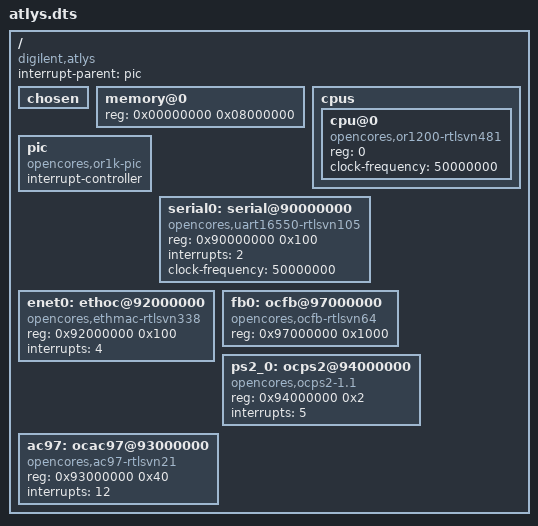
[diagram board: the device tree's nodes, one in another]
/dts-v1/;
/ {
	compatible = "digilent,atlys";

	#address-cells = <1>;
	#size-cells = <1>;
	interrupt-parent = <&pic>;

	chosen {
	};

	memory@0 {
		device_type = "memory";
		reg = <0x00000000 0x08000000>;
	};

	cpus {
		#address-cells = <1>;
		#size-cells = <0>;
		cpu@0 {
			compatible = "opencores,or1200-rtlsvn481";
			reg = <0>;
			clock-frequency = <50000000>;
		};
	};

	/*
	 * OR1K PIC is built into CPU and accessed via special purpose
	 * registers.  It is not addressable and, hence, has no 'reg'
	 * property.
	 */
	pic: pic {
		compatible = "opencores,or1k-pic";
		#interrupt-cells = <1>;
		interrupt-controller;
	};

	serial0: serial@90000000 {
		compatible = "opencores,uart16550-rtlsvn105", "ns16550a";
		reg = <0x90000000 0x100>;
		interrupts = <2>;
		clock-frequency = <50000000>;
	};

	enet0: ethoc@92000000 {
		compatible = "opencores,ethmac-rtlsvn338";
		reg = <0x92000000 0x100>;
		interrupts = <4>;
	};
	
	fb0: ocfb@97000000 {
	     	compatible = "opencores,ocfb-rtlsvn64";
		reg = <0x97000000 0x1000>;
	};

	ps2_0: ocps2@94000000 {
		compatible = "opencores,ocps2-1.1";
		reg = <0x94000000 0x2>;
		interrupts = <5>;
	};
/*
	ps2_1: ocps2@95000000 {
		compatible = "opencores,ocps2-1.1";
		reg = <0x95000000 0x2>;
		interrupts = <13>;
	};
*/
	ac97: ocac97@93000000 {
		compatible = "opencores,ac97-rtlsvn21";
		reg = <0x93000000 0x40>;
		interrupts = <12>;
	};
};
